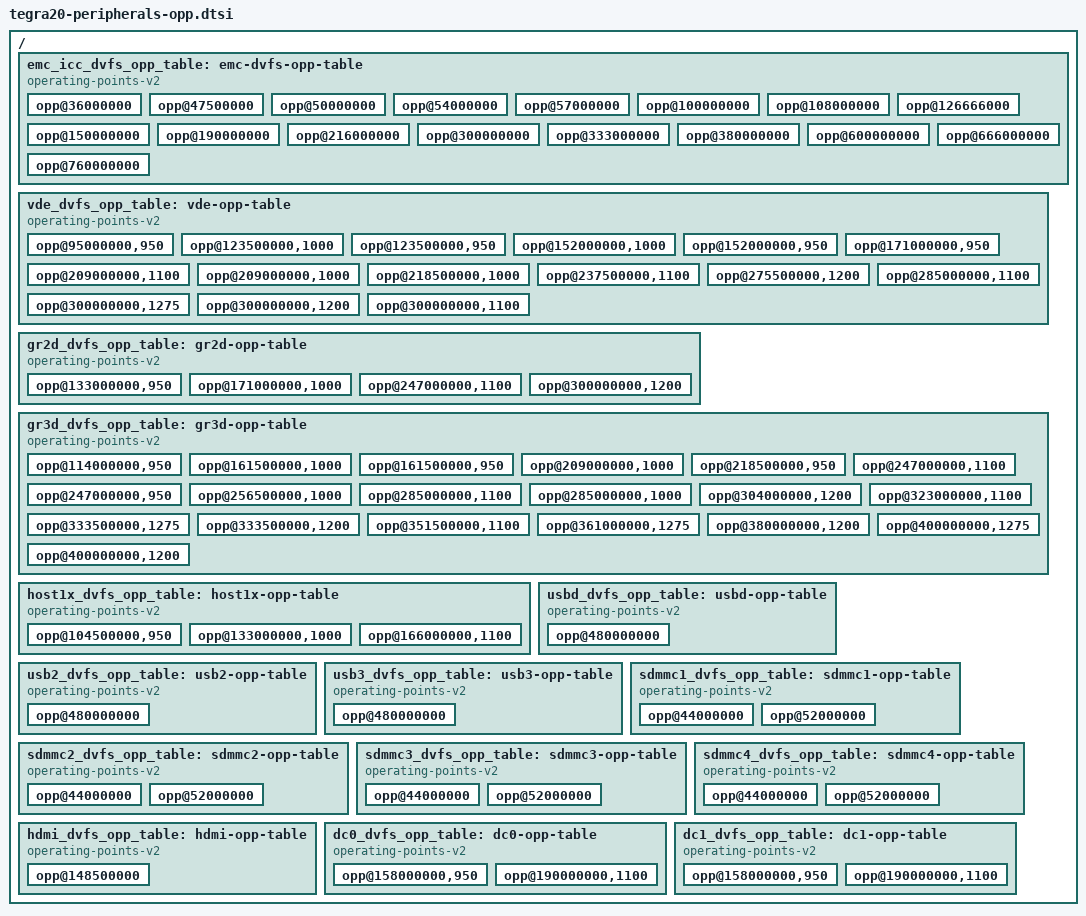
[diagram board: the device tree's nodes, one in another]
// SPDX-License-Identifier: GPL-2.0

/ {
	emc_icc_dvfs_opp_table: emc-dvfs-opp-table {
		compatible = "operating-points-v2";

		opp@36000000 {
			opp-microvolt = <950000 950000 1300000>;
			opp-hz = /bits/ 64 <36000000>;
		};

		opp@47500000 {
			opp-microvolt = <950000 950000 1300000>;
			opp-hz = /bits/ 64 <47500000>;
		};

		opp@50000000 {
			opp-microvolt = <950000 950000 1300000>;
			opp-hz = /bits/ 64 <50000000>;
		};

		opp@54000000 {
			opp-microvolt = <950000 950000 1300000>;
			opp-hz = /bits/ 64 <54000000>;
		};

		opp@57000000 {
			opp-microvolt = <950000 950000 1300000>;
			opp-hz = /bits/ 64 <57000000>;
		};

		opp@100000000 {
			opp-microvolt = <1000000 1000000 1300000>;
			opp-hz = /bits/ 64 <100000000>;
		};

		opp@108000000 {
			opp-microvolt = <1000000 1000000 1300000>;
			opp-hz = /bits/ 64 <108000000>;
		};

		opp@126666000 {
			opp-microvolt = <1000000 1000000 1300000>;
			opp-hz = /bits/ 64 <126666000>;
		};

		opp@150000000 {
			opp-microvolt = <1000000 1000000 1300000>;
			opp-hz = /bits/ 64 <150000000>;
		};

		opp@190000000 {
			opp-microvolt = <1000000 1000000 1300000>;
			opp-hz = /bits/ 64 <190000000>;
		};

		opp@216000000 {
			opp-microvolt = <1000000 1000000 1300000>;
			opp-hz = /bits/ 64 <216000000>;
		};

		opp@300000000 {
			opp-microvolt = <1000000 1000000 1300000>;
			opp-hz = /bits/ 64 <300000000>;
		};

		opp@333000000 {
			opp-microvolt = <1000000 1000000 1300000>;
			opp-hz = /bits/ 64 <333000000>;
		};

		opp@380000000 {
			opp-microvolt = <1100000 1100000 1300000>;
			opp-hz = /bits/ 64 <380000000>;
		};

		opp@600000000 {
			opp-microvolt = <1200000 1200000 1300000>;
			opp-hz = /bits/ 64 <600000000>;
		};

		opp@666000000 {
			opp-microvolt = <1200000 1200000 1300000>;
			opp-hz = /bits/ 64 <666000000>;
		};

		opp@760000000 {
			opp-microvolt = <1300000 1300000 1300000>;
			opp-hz = /bits/ 64 <760000000>;
		};
	};

	vde_dvfs_opp_table: vde-opp-table {
		compatible = "operating-points-v2";

		opp@95000000,950 {
			opp-microvolt = <950000 950000 1300000>;
			opp-hz = /bits/ 64 <95000000>;
			opp-supported-hw = <0x0001>;
		};

		opp@123500000,1000 {
			opp-microvolt = <1000000 1000000 1300000>;
			opp-hz = /bits/ 64 <123500000>;
			opp-supported-hw = <0x0001>;
		};

		opp@123500000,950 {
			opp-microvolt = <950000 950000 1300000>;
			opp-hz = /bits/ 64 <123500000>;
			opp-supported-hw = <0x0002>;
		};

		opp@152000000,1000 {
			opp-microvolt = <1000000 1000000 1300000>;
			opp-hz = /bits/ 64 <152000000>;
			opp-supported-hw = <0x0002>;
		};

		opp@152000000,950 {
			opp-microvolt = <950000 950000 1300000>;
			opp-hz = /bits/ 64 <152000000>;
			opp-supported-hw = <0x0004>;
		};

		opp@171000000,950 {
			opp-microvolt = <950000 950000 1300000>;
			opp-hz = /bits/ 64 <171000000>;
			opp-supported-hw = <0x0008>;
		};

		opp@209000000,1100 {
			opp-microvolt = <1100000 1100000 1300000>;
			opp-hz = /bits/ 64 <209000000>;
			opp-supported-hw = <0x0001>;
		};

		opp@209000000,1000 {
			opp-microvolt = <1000000 1000000 1300000>;
			opp-hz = /bits/ 64 <209000000>;
			opp-supported-hw = <0x0004>;
		};

		opp@218500000,1000 {
			opp-microvolt = <1000000 1000000 1300000>;
			opp-hz = /bits/ 64 <218500000>;
			opp-supported-hw = <0x0008>;
		};

		opp@237500000,1100 {
			opp-microvolt = <1100000 1100000 1300000>;
			opp-hz = /bits/ 64 <237500000>;
			opp-supported-hw = <0x0002>;
		};

		opp@275500000,1200 {
			opp-microvolt = <1200000 1200000 1300000>;
			opp-hz = /bits/ 64 <275500000>;
			opp-supported-hw = <0x0001>;
		};

		opp@285000000,1100 {
			opp-microvolt = <1100000 1100000 1300000>;
			opp-hz = /bits/ 64 <285000000>;
			opp-supported-hw = <0x0004>;
		};

		opp@300000000,1275 {
			opp-microvolt = <1275000 1275000 1300000>;
			opp-hz = /bits/ 64 <300000000>;
			opp-supported-hw = <0x0001>;
		};

		opp@300000000,1200 {
			opp-microvolt = <1200000 1200000 1300000>;
			opp-hz = /bits/ 64 <300000000>;
			opp-supported-hw = <0x0006>;
		};

		opp@300000000,1100 {
			opp-microvolt = <1100000 1100000 1300000>;
			opp-hz = /bits/ 64 <300000000>;
			opp-supported-hw = <0x0008>;
		};
	};

	gr2d_dvfs_opp_table: gr2d-opp-table {
		compatible = "operating-points-v2";

		opp@133000000,950 {
			opp-microvolt = <950000 950000 1300000>;
			opp-hz = /bits/ 64 <133000000>;
			opp-supported-hw = <0x000F>;
		};

		opp@171000000,1000 {
			opp-microvolt = <1000000 1000000 1300000>;
			opp-hz = /bits/ 64 <171000000>;
			opp-supported-hw = <0x000F>;
		};

		opp@247000000,1100 {
			opp-microvolt = <1100000 1100000 1300000>;
			opp-hz = /bits/ 64 <247000000>;
			opp-supported-hw = <0x000F>;
		};

		opp@300000000,1200 {
			opp-microvolt = <1200000 1200000 1300000>;
			opp-hz = /bits/ 64 <300000000>;
			opp-supported-hw = <0x000F>;
		};
	};

	gr3d_dvfs_opp_table: gr3d-opp-table {
		compatible = "operating-points-v2";

		opp@114000000,950 {
			opp-microvolt = <950000 950000 1300000>;
			opp-hz = /bits/ 64 <114000000>;
			opp-supported-hw = <0x0001>;
		};

		opp@161500000,1000 {
			opp-microvolt = <1000000 1000000 1300000>;
			opp-hz = /bits/ 64 <161500000>;
			opp-supported-hw = <0x0001>;
		};

		opp@161500000,950 {
			opp-microvolt = <950000 950000 1300000>;
			opp-hz = /bits/ 64 <161500000>;
			opp-supported-hw = <0x0002>;
		};

		opp@209000000,1000 {
			opp-microvolt = <1000000 1000000 1300000>;
			opp-hz = /bits/ 64 <209000000>;
			opp-supported-hw = <0x0002>;
		};

		opp@218500000,950 {
			opp-microvolt = <950000 950000 1300000>;
			opp-hz = /bits/ 64 <218500000>;
			opp-supported-hw = <0x0004>;
		};

		opp@247000000,1100 {
			opp-microvolt = <1100000 1100000 1300000>;
			opp-hz = /bits/ 64 <247000000>;
			opp-supported-hw = <0x0001>;
		};

		opp@247000000,950 {
			opp-microvolt = <950000 950000 1300000>;
			opp-hz = /bits/ 64 <247000000>;
			opp-supported-hw = <0x0008>;
		};

		opp@256500000,1000 {
			opp-microvolt = <1000000 1000000 1300000>;
			opp-hz = /bits/ 64 <256500000>;
			opp-supported-hw = <0x0004>;
		};

		opp@285000000,1100 {
			opp-microvolt = <1100000 1100000 1300000>;
			opp-hz = /bits/ 64 <285000000>;
			opp-supported-hw = <0x0002>;
		};

		opp@285000000,1000 {
			opp-microvolt = <1000000 1000000 1300000>;
			opp-hz = /bits/ 64 <285000000>;
			opp-supported-hw = <0x0008>;
		};

		opp@304000000,1200 {
			opp-microvolt = <1200000 1200000 1300000>;
			opp-hz = /bits/ 64 <304000000>;
			opp-supported-hw = <0x0001>;
		};

		opp@323000000,1100 {
			opp-microvolt = <1100000 1100000 1300000>;
			opp-hz = /bits/ 64 <323000000>;
			opp-supported-hw = <0x0004>;
		};

		opp@333500000,1275 {
			opp-microvolt = <1275000 1275000 1300000>;
			opp-hz = /bits/ 64 <333500000>;
			opp-supported-hw = <0x0001>;
		};

		opp@333500000,1200 {
			opp-microvolt = <1200000 1200000 1300000>;
			opp-hz = /bits/ 64 <333500000>;
			opp-supported-hw = <0x0002>;
		};

		opp@351500000,1100 {
			opp-microvolt = <1100000 1100000 1300000>;
			opp-hz = /bits/ 64 <351500000>;
			opp-supported-hw = <0x0008>;
		};

		opp@361000000,1275 {
			opp-microvolt = <1275000 1275000 1300000>;
			opp-hz = /bits/ 64 <361000000>;
			opp-supported-hw = <0x0002>;
		};

		opp@380000000,1200 {
			opp-microvolt = <1200000 1200000 1300000>;
			opp-hz = /bits/ 64 <380000000>;
			opp-supported-hw = <0x0004>;
		};

		opp@400000000,1275 {
			opp-microvolt = <1275000 1275000 1300000>;
			opp-hz = /bits/ 64 <400000000>;
			opp-supported-hw = <0x0004>;
		};

		opp@400000000,1200 {
			opp-microvolt = <1200000 1200000 1300000>;
			opp-hz = /bits/ 64 <400000000>;
			opp-supported-hw = <0x0008>;
		};
	};

	host1x_dvfs_opp_table: host1x-opp-table {
		compatible = "operating-points-v2";

		opp@104500000,950 {
			opp-microvolt = <950000 950000 1300000>;
			opp-hz = /bits/ 64 <104500000>;
			opp-supported-hw = <0x000F>;
		};

		opp@133000000,1000 {
			opp-microvolt = <1000000 1000000 1300000>;
			opp-hz = /bits/ 64 <133000000>;
			opp-supported-hw = <0x000F>;
		};

		opp@166000000,1100 {
			opp-microvolt = <1100000 1100000 1300000>;
			opp-hz = /bits/ 64 <166000000>;
			opp-supported-hw = <0x000F>;
		};
	};

	usbd_dvfs_opp_table: usbd-opp-table {
		compatible = "operating-points-v2";

		opp@480000000 {
			opp-microvolt = <1100000 1100000 1300000>;
			opp-hz = /bits/ 64 <480000000>;
		};
	};

	usb2_dvfs_opp_table: usb2-opp-table {
		compatible = "operating-points-v2";

		opp@480000000 {
			opp-microvolt = <1100000 1100000 1300000>;
			opp-hz = /bits/ 64 <480000000>;
		};
	};

	usb3_dvfs_opp_table: usb3-opp-table {
		compatible = "operating-points-v2";

		opp@480000000 {
			opp-microvolt = <1100000 1100000 1300000>;
			opp-hz = /bits/ 64 <480000000>;
		};
	};

	sdmmc1_dvfs_opp_table: sdmmc1-opp-table {
		compatible = "operating-points-v2";

		opp@44000000 {
			opp-microvolt = <950000 950000 1300000>;
			opp-hz = /bits/ 64 <44000000>;
		};

		opp@52000000 {
			opp-microvolt = <1000000 1000000 1300000>;
			opp-hz = /bits/ 64 <52000000>;
		};
	};

	sdmmc2_dvfs_opp_table: sdmmc2-opp-table {
		compatible = "operating-points-v2";

		opp@44000000 {
			opp-microvolt = <950000 950000 1300000>;
			opp-hz = /bits/ 64 <44000000>;
		};

		opp@52000000 {
			opp-microvolt = <1000000 1000000 1300000>;
			opp-hz = /bits/ 64 <52000000>;
		};
	};

	sdmmc3_dvfs_opp_table: sdmmc3-opp-table {
		compatible = "operating-points-v2";

		opp@44000000 {
			opp-microvolt = <950000 950000 1300000>;
			opp-hz = /bits/ 64 <44000000>;
		};

		opp@52000000 {
			opp-microvolt = <1000000 1000000 1300000>;
			opp-hz = /bits/ 64 <52000000>;
		};
	};

	sdmmc4_dvfs_opp_table: sdmmc4-opp-table {
		compatible = "operating-points-v2";

		opp@44000000 {
			opp-microvolt = <950000 950000 1300000>;
			opp-hz = /bits/ 64 <44000000>;
		};

		opp@52000000 {
			opp-microvolt = <1000000 1000000 1300000>;
			opp-hz = /bits/ 64 <52000000>;
		};
	};

	hdmi_dvfs_opp_table: hdmi-opp-table {
		compatible = "operating-points-v2";

		opp@148500000 {
			opp-microvolt = <1200000 1200000 1300000>;
			opp-hz = /bits/ 64 <148500000>;
		};
	};

	dc0_dvfs_opp_table: dc0-opp-table {
		compatible = "operating-points-v2";

		opp@158000000,950 {
			opp-microvolt = <950000 950000 1300000>;
			opp-hz = /bits/ 64 <158000000>;
			opp-supported-hw = <0x000F>;
		};

		opp@190000000,1100 {
			opp-microvolt = <1100000 1100000 1300000>;
			opp-hz = /bits/ 64 <190000000>;
			opp-supported-hw = <0x000F>;
		};
	};

	dc1_dvfs_opp_table: dc1-opp-table {
		compatible = "operating-points-v2";

		opp@158000000,950 {
			opp-microvolt = <950000 950000 1300000>;
			opp-hz = /bits/ 64 <158000000>;
			opp-supported-hw = <0x000F>;
		};

		opp@190000000,1100 {
			opp-microvolt = <1100000 1100000 1300000>;
			opp-hz = /bits/ 64 <190000000>;
			opp-supported-hw = <0x000F>;
		};
	};
};
